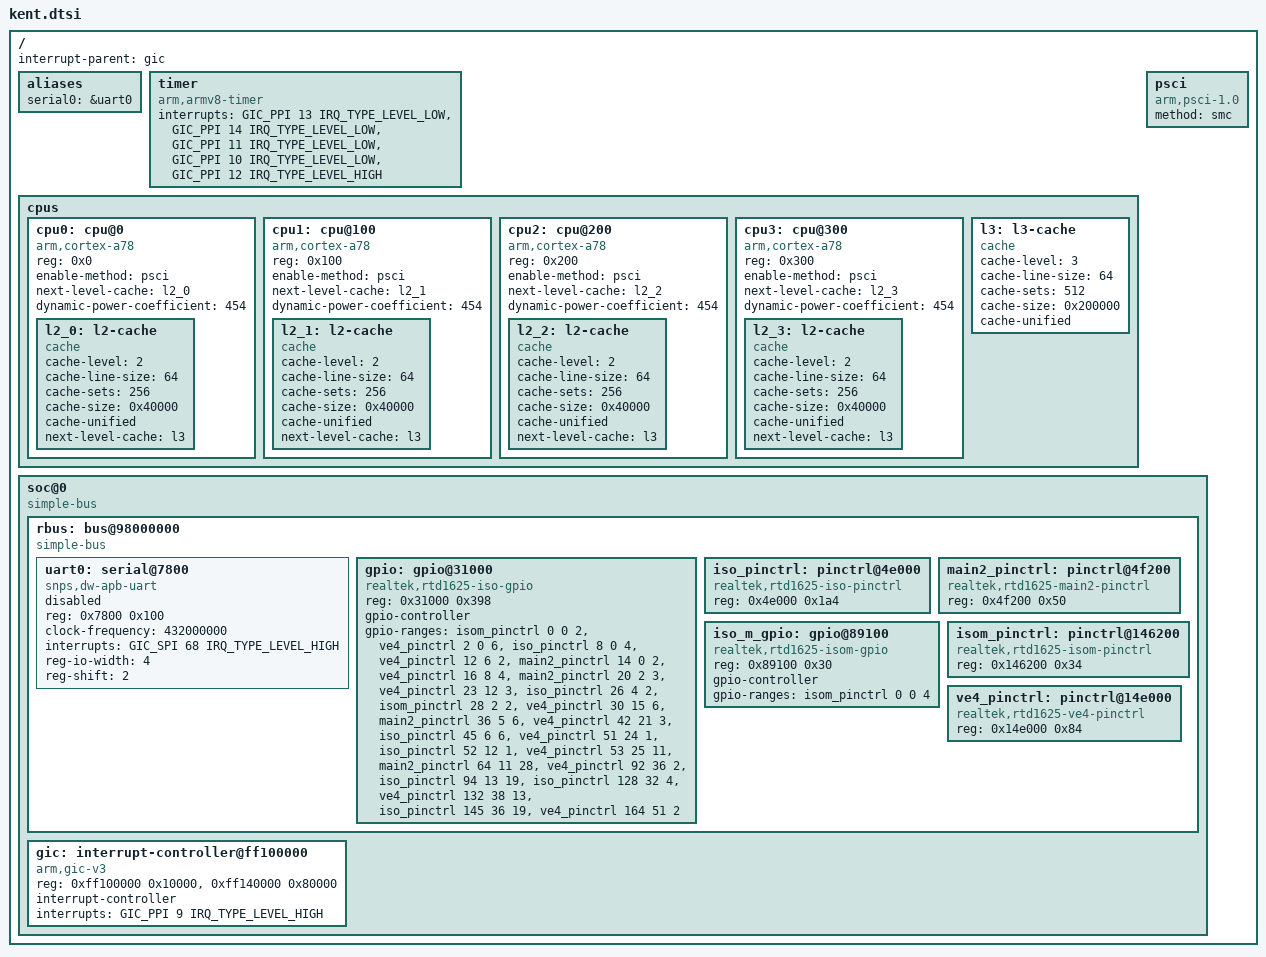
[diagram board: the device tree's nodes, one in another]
// SPDX-License-Identifier: GPL-2.0
/*
 * Realtek Kent SoC family
 *
 * Copyright (c) 2024 Realtek Semiconductor Corp.
 */

#include <dt-bindings/interrupt-controller/arm-gic.h>
#include <dt-bindings/interrupt-controller/irq.h>

/ {
	interrupt-parent = <&gic>;
	#address-cells = <2>;
	#size-cells = <2>;

	aliases {
		serial0 = &uart0;
	};

	timer {
		compatible = "arm,armv8-timer";
		interrupts = <GIC_PPI 13 IRQ_TYPE_LEVEL_LOW>,
			     <GIC_PPI 14 IRQ_TYPE_LEVEL_LOW>,
			     <GIC_PPI 11 IRQ_TYPE_LEVEL_LOW>,
			     <GIC_PPI 10 IRQ_TYPE_LEVEL_LOW>,
			     <GIC_PPI 12 IRQ_TYPE_LEVEL_HIGH>;
	};

	cpus {
		#address-cells = <1>;
		#size-cells = <0>;

		cpu0: cpu@0 {
			device_type = "cpu";
			compatible = "arm,cortex-a78";
			reg = <0x0>;
			enable-method = "psci";
			next-level-cache = <&l2_0>;
			dynamic-power-coefficient = <454>;
			#cooling-cells = <2>;

			l2_0: l2-cache {
				compatible = "cache";
				cache-level = <2>;
				cache-line-size = <64>;
				cache-sets = <256>;
				cache-size = <0x40000>;
				cache-unified;
				next-level-cache = <&l3>;
			};
		};

		cpu1: cpu@100 {
			device_type = "cpu";
			compatible = "arm,cortex-a78";
			reg = <0x100>;
			enable-method = "psci";
			next-level-cache = <&l2_1>;
			dynamic-power-coefficient = <454>;
			#cooling-cells = <2>;

			l2_1: l2-cache {
				compatible = "cache";
				cache-level = <2>;
				cache-line-size = <64>;
				cache-sets = <256>;
				cache-size = <0x40000>;
				cache-unified;
				next-level-cache = <&l3>;
			};
		};

		cpu2: cpu@200 {
			device_type = "cpu";
			compatible = "arm,cortex-a78";
			reg = <0x200>;
			enable-method = "psci";
			next-level-cache = <&l2_2>;
			dynamic-power-coefficient = <454>;
			#cooling-cells = <2>;

			l2_2: l2-cache {
				compatible = "cache";
				cache-level = <2>;
				cache-line-size = <64>;
				cache-sets = <256>;
				cache-size = <0x40000>;
				cache-unified;
				next-level-cache = <&l3>;
			};
		};

		cpu3: cpu@300 {
			device_type = "cpu";
			compatible = "arm,cortex-a78";
			reg = <0x300>;
			enable-method = "psci";
			next-level-cache = <&l2_3>;
			dynamic-power-coefficient = <454>;
			#cooling-cells = <2>;

			l2_3: l2-cache {
				compatible = "cache";
				cache-level = <2>;
				cache-line-size = <64>;
				cache-sets = <256>;
				cache-size = <0x40000>;
				cache-unified;
				next-level-cache = <&l3>;
			};
		};

		l3: l3-cache {
			compatible = "cache";
			cache-level = <3>;
			cache-line-size = <64>;
			cache-sets = <512>;
			cache-size = <0x200000>;
			cache-unified;
		};
	};

	psci: psci {
		compatible = "arm,psci-1.0";
		method = "smc";
	};

	soc@0 {
		compatible = "simple-bus";
		ranges = <0x0 0x0 0x0 0x40000>, /* boot code */
			 <0x98000000 0x0 0x98000000 0xef0000>, /* rbus */
			 <0xa0000000 0x0 0xa0000000 0x10000000>, /* PCIE */
			 <0xff000000 0x0 0xff000000 0x200000>; /* GIC */
		#address-cells = <1>;
		#size-cells = <1>;

		rbus: bus@98000000 {
			compatible = "simple-bus";
			ranges = <0x0 0x98000000 0xef0000>,
				 <0xa0000000 0xa0000000 0x10000000>; /* PCIE */
			#address-cells = <1>;
			#size-cells = <1>;

			uart0: serial@7800 {
				compatible = "snps,dw-apb-uart";
				reg = <0x7800 0x100>;
				clock-frequency = <432000000>;
				interrupts = <GIC_SPI 68 IRQ_TYPE_LEVEL_HIGH>;
				reg-io-width = <4>;
				reg-shift = <2>;
				status = "disabled";
			};

			gpio: gpio@31000 {
				compatible = "realtek,rtd1625-iso-gpio";
				reg = <0x31000 0x398>;
				gpio-controller;
				gpio-ranges = <&isom_pinctrl 0 0 2>,
					      <&ve4_pinctrl 2 0 6>,
					      <&iso_pinctrl 8 0 4>,
					      <&ve4_pinctrl 12 6 2>,
					      <&main2_pinctrl 14 0 2>,
					      <&ve4_pinctrl 16 8 4>,
					      <&main2_pinctrl 20 2 3>,
					      <&ve4_pinctrl 23 12 3>,
					      <&iso_pinctrl 26 4 2>,
					      <&isom_pinctrl 28 2 2>,
					      <&ve4_pinctrl 30 15 6>,
					      <&main2_pinctrl 36 5 6>,
					      <&ve4_pinctrl 42 21 3>,
					      <&iso_pinctrl 45 6 6>,
					      <&ve4_pinctrl 51 24 1>,
					      <&iso_pinctrl 52 12 1>,
					      <&ve4_pinctrl 53 25 11>,
					      <&main2_pinctrl 64 11 28>,
					      <&ve4_pinctrl 92 36 2>,
					      <&iso_pinctrl 94 13 19>,
					      <&iso_pinctrl 128 32 4>,
					      <&ve4_pinctrl 132 38 13>,
					      <&iso_pinctrl 145 36 19>,
					      <&ve4_pinctrl 164 51 2>;
				#gpio-cells = <2>;
			};

			iso_pinctrl: pinctrl@4e000 {
				compatible = "realtek,rtd1625-iso-pinctrl";
				reg = <0x4e000 0x1a4>;
			};

			main2_pinctrl: pinctrl@4f200 {
				compatible = "realtek,rtd1625-main2-pinctrl";
				reg = <0x4f200 0x50>;
			};

			iso_m_gpio: gpio@89100 {
				compatible = "realtek,rtd1625-isom-gpio";
				reg = <0x89100 0x30>;
				gpio-controller;
				gpio-ranges = <&isom_pinctrl 0 0 4>;
				#gpio-cells = <2>;
			};

			isom_pinctrl: pinctrl@146200 {
				compatible = "realtek,rtd1625-isom-pinctrl";
				reg = <0x146200 0x34>;
			};

			ve4_pinctrl: pinctrl@14e000 {
				compatible = "realtek,rtd1625-ve4-pinctrl";
				reg = <0x14e000 0x84>;
			};
		};

		gic: interrupt-controller@ff100000 {
			compatible = "arm,gic-v3";
			reg = <0xff100000 0x10000>,
			      <0xff140000 0x80000>;
			interrupt-controller;
			interrupts = <GIC_PPI 9 IRQ_TYPE_LEVEL_HIGH>;
			#address-cells = <1>;
			#interrupt-cells = <3>;
			#size-cells = <1>;
		};
	};
};
